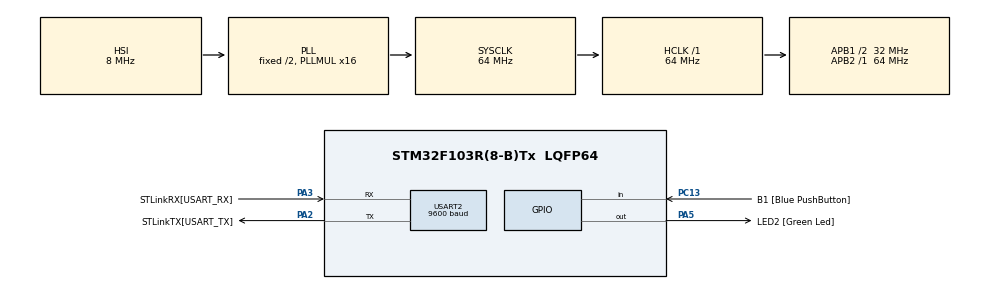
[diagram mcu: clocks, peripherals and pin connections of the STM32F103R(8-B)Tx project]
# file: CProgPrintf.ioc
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Mcu.Family=STM32F1
Mcu.Name=STM32F103R(8-B)Tx
Mcu.Package=LQFP64
NVIC.PriorityGroup=NVIC_PRIORITYGROUP_4
NVIC.TIM4_IRQn=true\:15\:0\:false\:false\:true\:false\:true\:true
NVIC.TimeBase=TIM4_IRQn
NVIC.TimeBaseIP=TIM4
PA13.Mode=Serial_Wire
PA13.Signal=SYS_JTMS-SWDIO
PA14.Mode=Serial_Wire
PA14.Signal=SYS_JTCK-SWCLK
PA2.GPIO_Label=STLinkTX[USART_TX]
PA2.Mode=Asynchronous
PA2.Signal=USART2_TX
PA3.GPIO_Label=STLinkRX[USART_RX]
PA3.Mode=Asynchronous
PA3.Signal=USART2_RX
PA5.GPIO_Label=LED2 [Green Led]
PA5.Signal=GPIO_Output
PC13-TAMPER-RTC.GPIO_Label=B1 [Blue PushButton]
PC13-TAMPER-RTC.Signal=GPIO_Input
ProjectManager.HeapSize=0x200
ProjectManager.StackSize=0x400
ProjectManager.TargetToolchain=STM32CubeIDE
RCC.AHBFreq_Value=64000000
RCC.APB1CLKDivider=RCC_HCLK_DIV2
RCC.APB1Freq_Value=32000000
RCC.APB1TimFreq_Value=64000000
RCC.APB2Freq_Value=64000000
RCC.APB2TimFreq_Value=64000000
RCC.HCLKFreq_Value=64000000
RCC.PLLMUL=RCC_PLL_MUL16
RCC.SYSCLKFreq_VALUE=64000000
RCC.SYSCLKSource=RCC_SYSCLKSOURCE_PLLCLK
RCC.USBFreq_Value=64000000
USART2.BaudRate=9600
USART2.VirtualMode=VM_ASYNC
VP_SYS_VS_tim4.Mode=TIM4
board=custom

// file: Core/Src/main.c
/* USER CODE BEGIN Header */
/**
  ******************************************************************************
  * @file           : main.c
  * @brief          : Main program body
  ******************************************************************************
  * @attention
  *
  * Copyright (c) 2024 STMicroelectronics.
  * All rights reserved.
  *
  * This software is licensed under terms that can be found in the LICENSE file
  * in the root directory of this software component.
  * If no LICENSE file comes with this software, it is provided AS-IS.
  *
  ******************************************************************************
  */
/* USER CODE END Header */
#include "main.h"

/* USER CODE BEGIN Includes */
#include <stdio.h>
#include "myprintf.h"
/* USER CODE END Includes */

UART_HandleTypeDef huart2;

void SystemClock_Config(void);
static void MX_GPIO_Init(void);
static void MX_USART2_UART_Init(void);

int main(void)
{

  /* MCU Configuration--------------------------------------------------------*/

  /* Reset of all peripherals, Initializes the Flash interface and the Systick. */
  HAL_Init();

  /* Configure the system clock */
  SystemClock_Config();

  /* Initialize all configured peripherals */
  MX_GPIO_Init();
  MX_USART2_UART_Init();
  /* USER CODE BEGIN 2 */
  RetargetInit(&huart2);
  /* USER CODE END 2 */

  /* Infinite loop */
  /* USER CODE BEGIN WHILE */
  //printf("\nHi, my name is Alberto!");
  uint8_t ch = 0x42;
  uint16_t count = 0;
  while (1)
  {
	  //printf("\nHi, my name is Dionisio Alberto Mancilla Delgado!");
	  /*
	  HAL_GPIO_TogglePin(LED2_GPIO_Port, LED2_Pin);
	  HAL_Delay(1000);
	  HAL_UART_Receive(&huart2, &ch,(uint16_t)1,HAL_MAX_DELAY);
	  ch = ch+1;
	  HAL_Delay(10);
	  HAL_UART_Transmit(&huart2, &ch,(uint16_t)1,HAL_MAX_DELAY);
	  HAL_Delay(10);
	  */
	  HAL_Delay(100);
	  for(count=200; count<=400; count+=10){
		  printf("\n%d,%d", count, 0);
		  HAL_Delay(1);
	  }
	  count = 400;
	  for(count; count>=200; count-=10){
		  printf("\n%d,%d", count, 1);
	 	  HAL_Delay(1);
	  }

    /* USER CODE END WHILE */

  }
}

void SystemClock_Config(void)
{
  RCC_OscInitTypeDef RCC_OscInitStruct = {0};
  RCC_ClkInitTypeDef RCC_ClkInitStruct = {0};

  /** Initializes the RCC Oscillators according to the specified parameters
  * in the RCC_OscInitTypeDef structure.
  */
  RCC_OscInitStruct.OscillatorType = RCC_OSCILLATORTYPE_HSI;
  RCC_OscInitStruct.HSIState = RCC_HSI_ON;
  RCC_OscInitStruct.HSICalibrationValue = RCC_HSICALIBRATION_DEFAULT;
  RCC_OscInitStruct.PLL.PLLState = RCC_PLL_ON;
  RCC_OscInitStruct.PLL.PLLSource = RCC_PLLSOURCE_HSI_DIV2;
  RCC_OscInitStruct.PLL.PLLMUL = RCC_PLL_MUL16;
  if (HAL_RCC_OscConfig(&RCC_OscInitStruct) != HAL_OK)
  {
    Error_Handler();
  }

  /** Initializes the CPU, AHB and APB buses clocks
  */
  RCC_ClkInitStruct.ClockType = RCC_CLOCKTYPE_HCLK|RCC_CLOCKTYPE_SYSCLK
                              |RCC_CLOCKTYPE_PCLK1|RCC_CLOCKTYPE_PCLK2;
  RCC_ClkInitStruct.SYSCLKSource = RCC_SYSCLKSOURCE_PLLCLK;
  RCC_ClkInitStruct.AHBCLKDivider = RCC_SYSCLK_DIV1;
  RCC_ClkInitStruct.APB1CLKDivider = RCC_HCLK_DIV2;
  RCC_ClkInitStruct.APB2CLKDivider = RCC_HCLK_DIV1;

  if (HAL_RCC_ClockConfig(&RCC_ClkInitStruct, FLASH_LATENCY_2) != HAL_OK)
  {
    Error_Handler();
  }
}

static void MX_USART2_UART_Init(void)
{

  huart2.Instance = USART2;
  huart2.Init.BaudRate = 9600;
  huart2.Init.WordLength = UART_WORDLENGTH_8B;
  huart2.Init.StopBits = UART_STOPBITS_1;
  huart2.Init.Parity = UART_PARITY_NONE;
  huart2.Init.Mode = UART_MODE_TX_RX;
  huart2.Init.HwFlowCtl = UART_HWCONTROL_NONE;
  huart2.Init.OverSampling = UART_OVERSAMPLING_16;
  if (HAL_UART_Init(&huart2) != HAL_OK)
  {
    Error_Handler();
  }

}

static void MX_GPIO_Init(void)
{
  GPIO_InitTypeDef GPIO_InitStruct = {0};

  /* GPIO Ports Clock Enable */
  __HAL_RCC_GPIOC_CLK_ENABLE();
  __HAL_RCC_GPIOA_CLK_ENABLE();

  /*Configure GPIO pin Output Level */
  HAL_GPIO_WritePin(LED2_GPIO_Port, LED2_Pin, GPIO_PIN_RESET);

  /*Configure GPIO pin : B1_Pin */
  GPIO_InitStruct.Pin = B1_Pin;
  GPIO_InitStruct.Mode = GPIO_MODE_INPUT;
  GPIO_InitStruct.Pull = GPIO_NOPULL;
  HAL_GPIO_Init(B1_GPIO_Port, &GPIO_InitStruct);

  /*Configure GPIO pin : LED2_Pin */
  GPIO_InitStruct.Pin = LED2_Pin;
  GPIO_InitStruct.Mode = GPIO_MODE_OUTPUT_PP;
  GPIO_InitStruct.Pull = GPIO_NOPULL;
  GPIO_InitStruct.Speed = GPIO_SPEED_FREQ_LOW;
  HAL_GPIO_Init(LED2_GPIO_Port, &GPIO_InitStruct);

}

void HAL_TIM_PeriodElapsedCallback(TIM_HandleTypeDef *htim)
{
  if (htim->Instance == TIM4) {
    HAL_IncTick();
  }
}

void Error_Handler(void)
{
  __disable_irq();
  while (1)
  {
  }
}
